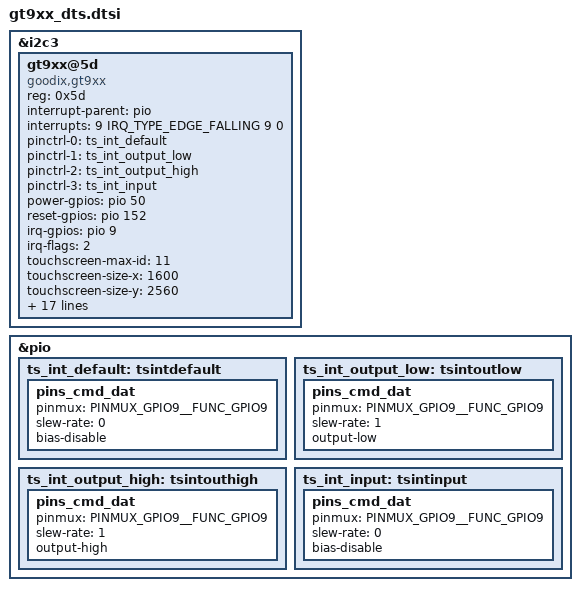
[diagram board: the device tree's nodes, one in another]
// SPDX-License-Identifier: GPL-2.0+
/*
 * Copyright (c) 2019 MediaTek Inc.
 */
&i2c3 {
	gt9xx@5d {
		compatible = "goodix,gt9xx";
		reg = <0x5d>; 
		status = "okay";
		interrupt-parent = <&pio>;
		interrupts = <9 IRQ_TYPE_EDGE_FALLING 9 0>;
		pinctrl-names = "default", "int-output-low","int-output-high", "int-input";
		pinctrl-0 = <&ts_int_default>;
		pinctrl-1 = <&ts_int_output_low>;
		pinctrl-2 = <&ts_int_output_high>;
		pinctrl-3 = <&ts_int_input>;
	
		power-gpios = <&pio 50 0>;
		reset-gpios = <&pio 152 0>;
		irq-gpios = <&pio 9 0>;
		irq-flags = <2>;
	
		touchscreen-max-id = <11>;
		touchscreen-size-x = <1600>;
		touchscreen-size-y = <2560>;
		touchscreen-max-w = <512>;
		touchscreen-max-p = <512>;
		touchscreen-key-map = <172>, <158>; /*KEY_HOMEPAGE=172, KEY_BACK=158，KEY_MENU=139*/
		goodix,slide-wakeup = <0>;
		goodix,type-a-report = <0>;
		goodix,driver-send-cfg = <1>;
		goodix,resume-in-workqueue = <0>;
		goodix,int-sync = <1>;
		goodix,swap-x2y = <0>;
		goodix,reverse-x = <1>;
		goodix,reverse-y = <1>;
		goodix,esd-protect = <1>;
		goodix,auto-update-cfg = <0>;
		goodix,power-off-sleep = <0>;
		goodix,pen-suppress-finger = <0>;
		goodix,cfg-group0 = [
			00 40 06 00 0A 05 35 00 01 18 28 0F 5A 41 03 05 00 00 00 00 00 00 35 18 1A 1E 14 90 30 AA 28 2A 15 0E 00 00 00 23 02 2C 00 05 00 00 00 05 1E 64 00 28 00 19 41 94 D5 02 07 1E 00 04 9B 1B 00 8B 21 00 80 28 00 76 31 00 6F 3B 00 6F 00 00 00 00 00 00 00 00 00 00 00 00 00 00 00 00 00 00 00 00 00 00 00 00 00 00 00 00 C2 00 00 00 00 00 00 00 19 18 17 16 15 14 11 10 0F 0E 0D 0C 09 08 07 06 05 04 01 00 FF FF FF FF FF FF FF FF FF FF 00 02 04 06 07 08 0A 0C 0D 0E 0F 10 11 12 13 14 19 1B 1C 1E 1F 20 21 22 23 24 25 26 27 28 29 2A FF FF FF FF FF FF FF FF FF FF C1 01
		];
	};
};

&pio {
	ts_int_default: tsintdefault {
		pins_cmd_dat {
			pinmux = <PINMUX_GPIO9__FUNC_GPIO9>;
			slew-rate = <0>;
			bias-disable;
		};
	};
	ts_int_output_low: tsintoutlow {
		pins_cmd_dat {
			pinmux = <PINMUX_GPIO9__FUNC_GPIO9>;
			slew-rate = <1>;
			output-low;
		};
	};
	ts_int_output_high: tsintouthigh {
		pins_cmd_dat {
			pinmux = <PINMUX_GPIO9__FUNC_GPIO9>;
			slew-rate = <1>;
			output-high;
		};
	};
	ts_int_input: tsintinput {
		pins_cmd_dat {
			pinmux = <PINMUX_GPIO9__FUNC_GPIO9>;
			slew-rate = <0>;
			bias-disable;
		};
	};
};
